AUTOSAR XML (schema 4-2-2)
package /SensorActuator_ICU
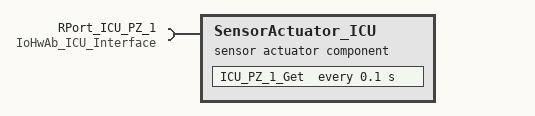
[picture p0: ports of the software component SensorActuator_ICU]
  sensor actuator sw component type SensorActuator_ICU
    require port RPort_ICU_PZ_1: required-interface=IoHwAb_ICU_Interface
    behavior IB_SensorActuator_ICU
      timing event TimingEvent_0: start-on-event=ICU_PZ_1_Get, period=0.1
      runnable ICU_PZ_1_Get: symbol=ICU_PZ_1_Get_func
        sync call SynchronousServerCallPoint_0: operation=RPort_ICU_PZ_1.IoHwAb_ICU_Get
